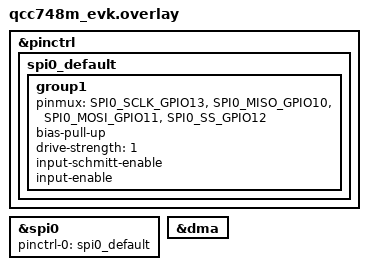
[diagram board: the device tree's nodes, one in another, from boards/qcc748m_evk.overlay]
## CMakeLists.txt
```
# Copyright (c) Qualcomm Technologies, Inc. and/or its subsidiaries.
# SPDX-License-Identifier: BSD-3-Clause

cmake_minimum_required(VERSION 3.20.0)
find_package(Zephyr REQUIRED HINTS $ENV{ZEPHYR_BASE})
project(pytest_shell)

target_sources(app PRIVATE src/main.c)
```

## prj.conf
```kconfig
# Copyright (c) Qualcomm Technologies, Inc. and/or its subsidiaries.
# SPDX-License-Identifier: BSD-3-Clause

# Shell on UART
CONFIG_SHELL=y
CONFIG_SHELL_BACKEND_SERIAL=y
CONFIG_QCOM_SPI_SHELL=y

# SPI
CONFIG_SPI=y
CONFIG_SPI_SLAVE=y
CONFIG_QCOM_SPI_SHELL_BUFFER_SIZE=65536

# Logging
CONFIG_LOG=y
CONFIG_SPI_LOG_LEVEL_INF=y

# Heap for buffers
CONFIG_HEAP_MEM_POOL_SIZE=8192

# Thread stack
CONFIG_MAIN_STACK_SIZE=4096
CONFIG_SHELL_STACK_SIZE=4096
```

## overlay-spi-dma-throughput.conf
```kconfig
# Copyright (c) Qualcomm Technologies, Inc. and/or its subsidiaries.
# SPDX-License-Identifier: BSD-3-Clause

# SPI DMA mode, sized for the multi-block throughput run.
#
# The throughput commands describe a whole run as one transaction of four
# 64-KB blocks, so CS stays asserted end to end and the slave never has to
# re-arm between blocks.  The HAL splits each DMA block into LLI entries of
# 4064 bytes drawn from a per-channel pool, so a 64-KB block costs 17 entries.
#
# This is scoped to the throughput configuration rather than raised globally.
CONFIG_DMA=y
CONFIG_SPI_QCC74X_DMA=y
CONFIG_DMA_CH_TRANSFER_LLI_MAX=72
CONFIG_SPI_LOG_LEVEL_ERR=y

# spi_shell places its fixed buffers in aligned, non-cacheable internal RAM,
# so the DMA path can use them directly without a heap bounce buffer.
CONFIG_PSRAM=n
CONFIG_HEAP_MEM_POOL_SIZE=8192
```

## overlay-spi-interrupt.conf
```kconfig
# Copyright (c) Qualcomm Technologies, Inc. and/or its subsidiaries.
# SPDX-License-Identifier: BSD-3-Clause

# Enable interrupt-mode SPI for the slave hardware timeout (STO) path.
CONFIG_SPI_QCC74X_INTERRUPT=y
CONFIG_SPI_QCC74X_INTERRUPT_SYNC=y
CONFIG_SPI_ASYNC=y
```

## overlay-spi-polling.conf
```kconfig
# Copyright (c) Qualcomm Technologies, Inc. and/or its subsidiaries.
# SPDX-License-Identifier: BSD-3-Clause

# SPI Polling mode
CONFIG_SPI_QCC74X_INTERRUPT=n
CONFIG_SPI_ASYNC=n
```

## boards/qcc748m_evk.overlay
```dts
/*
 * Copyright (c) Qualcomm Technologies, Inc. and/or its subsidiaries.
 * SPDX-License-Identifier: BSD-3-Clause
 *
 * QCC748M EVK board overlay for SPI shell test
 * Default (dual-board) pinmux: SCLK=GPIO13, MISO=GPIO10, MOSI=GPIO11, SS=GPIO12
 * Single-board scenarios override spi0's pinctrl with qcc748m_evk_single.overlay
 * to use the GPIO29/34/31/24 pin group.
 */

&pinctrl {
	status = "okay";
	spi0_default: spi0_default {
		group1 {
			pinmux = <SPI0_SCLK_GPIO13>,
				<SPI0_MISO_GPIO10>,
				<SPI0_MOSI_GPIO11>,
				<SPI0_SS_GPIO12>;
			bias-pull-up;
			drive-strength = <1>;
			input-schmitt-enable;
			input-enable;
		};
	};
};

&spi0 {
	status = "okay";
	pinctrl-0 = <&spi0_default>;
	pinctrl-names = "default";
};

&dma {
	status = "okay";
};
```

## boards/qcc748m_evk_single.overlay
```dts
/*
 * Copyright (c) Qualcomm Technologies, Inc. and/or its subsidiaries.
 * SPDX-License-Identifier: BSD-3-Clause
 *
 * Single-board pinmux for the GPIO29/34/31/24 wiring.
 *
 * The board overlay selects GPIO13/10/11/12 for dual-board wiring by
 * default.  This overlay only replaces spi0's active pinctrl state for
 * single-board scenarios; the rest of the board overlay remains unchanged.
 */

&pinctrl {
	status = "okay";
	spi0_single_default: spi0_single_default {
		group1 {
			pinmux = <SPI0_SCLK_GPIO29>,
				<SPI0_MISO_GPIO34>,
				<SPI0_MOSI_GPIO31>,
				<SPI0_SS_GPIO24>;
			bias-pull-up;
			drive-strength = <1>;
			input-schmitt-enable;
			input-enable;
		};
	};
};

&spi0 {
	status = "okay";
	pinctrl-0 = <&spi0_single_default>;
	pinctrl-names = "default";
};

&dma {
	status = "okay";
};
```

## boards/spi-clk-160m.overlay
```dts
/*
 * Copyright (c) Qualcomm Technologies, Inc. and/or its subsidiaries.
 * SPDX-License-Identifier: BSD-3-Clause
 *
 * Raise the SPI clock source so a genuine 40 MHz SCLK is reachable.
 *
 * SCLK is derived as spi_clk / (2 * (SPI_PRD_D + 1)).  Even the smallest
 * divider halves the source clock, so the SoC default source -- xclk, the
 * 40 MHz crystal -- caps SCLK at 20 MHz.  A 40 MHz request is not rejected in
 * that configuration; it is silently served at 20 MHz.  Selecting MCU MUXPLL
 * 160M gives the driver enough headroom to land on a true 40 MHz SCLK, which
 * doubles the master->slave DMA throughput (16.8 -> 39.6 Mbps).
 *
 * This is applied only to the configurations that need a real 40 MHz SCLK.  The
 * rest stay on the SoC default source on purpose, because that is what an
 * application gets without an overlay, and running them at an effective 20 MHz
 * keeps that path covered.
 */

&spi0 {
	clocks = <&clock0 QC7XX_PERIPHERAL_SPI0 QC7XX_SPI_CLK_MCU_MUXPLL_160M>;
};
```

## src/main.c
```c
/*
 * Copyright (c) Qualcomm Technologies, Inc. and/or its subsidiaries.
 * SPDX-License-Identifier: BSD-3-Clause
 *
 * SPI Shell Test Application
 * Provides shell commands for dual-board SPI master/slave testing.
 */

#include <zephyr/kernel.h>
#include <zephyr/logging/log.h>

LOG_MODULE_REGISTER(spi_shell_test, LOG_LEVEL_INF);

int main(void)
{
	LOG_INF("qcom spi Shell Test Application started");
	LOG_INF("Use 'qcom spi' commands to configure and test SPI");
	LOG_INF("Both Master and Slave roles are supported at runtime");
	return 0;
}
```
